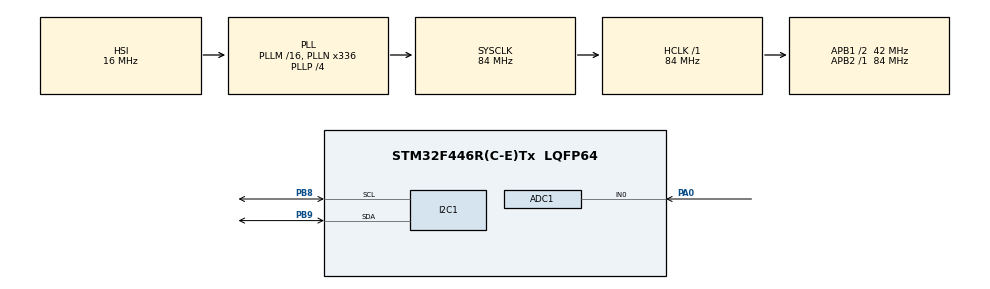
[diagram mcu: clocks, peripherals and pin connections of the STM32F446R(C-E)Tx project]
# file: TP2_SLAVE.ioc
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ADC1.Channel-0\#ChannelRegularConversion=ADC_CHANNEL_0
ADC1.Channel-1\#ChannelInjectedConversion=ADC_CHANNEL_0
ADC1.ContinuousConvMode=ENABLE
ADC1.EnableAnalogWatchDog=false
ADC1.InjNumberOfConversion=1
ADC1.InjectedOffset-1\#ChannelInjectedConversion=0
ADC1.InjectedRank-1\#ChannelInjectedConversion=1
ADC1.NbrOfConversion=1
ADC1.NbrOfConversionFlag=1
ADC1.Rank-0\#ChannelRegularConversion=1
ADC1.SamplingTime-0\#ChannelRegularConversion=ADC_SAMPLETIME_480CYCLES
ADC1.SamplingTime-1\#ChannelInjectedConversion=ADC_SAMPLETIME_3CYCLES
ADC1.master=1
I2C1.OwnAddress=0x13
Mcu.Family=STM32F4
Mcu.Name=STM32F446R(C-E)Tx
Mcu.Package=LQFP64
NVIC.I2C1_ER_IRQn=true\:0\:0\:false\:false\:true\:true\:true\:true
NVIC.I2C1_EV_IRQn=true\:0\:0\:false\:false\:true\:true\:true\:true
NVIC.PriorityGroup=NVIC_PRIORITYGROUP_0
PA0-WKUP.Signal=ADCx_IN0
PB8.Mode=I2C
PB8.Signal=I2C1_SCL
PB9.Mode=I2C
PB9.Signal=I2C1_SDA
ProjectManager.HeapSize=0x200
ProjectManager.StackSize=0x400
ProjectManager.TargetToolchain=STM32CubeIDE
RCC.48MHZClocksFreq_Value=84000000
RCC.AHBFreq_Value=84000000
RCC.APB1CLKDivider=RCC_HCLK_DIV2
RCC.APB1Freq_Value=42000000
RCC.APB1TimFreq_Value=84000000
RCC.APB2Freq_Value=84000000
RCC.APB2TimFreq_Value=84000000
RCC.CortexFreq_Value=84000000
RCC.FLatency-AdvancedSettings=FLASH_LATENCY_2
RCC.HCLKFreq_Value=84000000
RCC.HSE_VALUE=8000000
RCC.HSI_VALUE=16000000
RCC.PLLN=336
RCC.PLLP=RCC_PLLP_DIV4
RCC.SYSCLKFreq_VALUE=84000000
RCC.SYSCLKSource=RCC_SYSCLKSOURCE_PLLCLK
RCC.USBFreq_Value=168000000
RCC.VCOOutputFreq_Value=336000000
SH.ADCx_IN0.0=ADC1_IN0,IN0
board=NUCLEO-F446RE

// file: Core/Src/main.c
/* USER CODE BEGIN Header */
/**
  ******************************************************************************
  * @file           : main.c
  * @brief          : TP2 SLAVE - STM32F446RE I2C + ADC
  ******************************************************************************
  * Role of this board:
  * - I2C1 Slave on PB8/PB9.
  * - Own 7-bit address: 0x13.
  * - ADC1 input on PA0 / ADC1_IN0.
  * - Sends the ADC value to the Master as 2 bytes: MSB then LSB.
  ******************************************************************************
  */
/* USER CODE END Header */
#include "main.h"

/* USER CODE BEGIN Includes */
#include <stdio.h>
#include <string.h>
/* USER CODE END Includes */

ADC_HandleTypeDef hadc1;

I2C_HandleTypeDef hi2c1;

void SystemClock_Config(void);
static void MX_GPIO_Init(void);
static void MX_ADC1_Init(void);
static void MX_I2C1_Init(void);
/* USER CODE BEGIN PFP */
static uint16_t ADC_Read(void)
{
    HAL_ADC_Start(&hadc1);
    HAL_ADC_PollForConversion(&hadc1, HAL_MAX_DELAY);
    uint16_t val = (uint16_t)HAL_ADC_GetValue(&hadc1);
    HAL_ADC_Stop(&hadc1);
    return val;
}
/* USER CODE END PFP */

/* USER CODE BEGIN 0 */
volatile uint8_t cmd_received = 0;
volatile uint8_t tx_done = 0;
static uint8_t rx_buf[1] = {0};
static uint8_t tx_buf[2] = {0, 0};

void HAL_I2C_AddrCallback(I2C_HandleTypeDef *hi2c,
uint8_t TransferDirection,
uint16_t AddrMatchCode)
{
    if (TransferDirection == I2C_DIRECTION_TRANSMIT)
    {
        /* Master writing -> Slave receives */
        HAL_I2C_Slave_Seq_Receive_IT(hi2c, rx_buf, 1,
                I2C_FIRST_AND_LAST_FRAME);
    }
    else
    {
        /* Master reading -> Slave sends */
        HAL_I2C_Slave_Seq_Transmit_IT(hi2c, tx_buf, 2,
                I2C_FIRST_AND_LAST_FRAME);
    }
}

/* Called when slave has fully received 'Size' bytes from master */
void HAL_I2C_SlaveRxCpltCallback(I2C_HandleTypeDef *hi2c)
{
    HAL_I2C_EnableListen_IT(hi2c);
}

/* Called when slave has fully transmitted 'Size' bytes to master */
void HAL_I2C_SlaveTxCpltCallback(I2C_HandleTypeDef *hi2c)
{
    HAL_I2C_EnableListen_IT(hi2c);
}

void HAL_I2C_ListenCpltCallback(I2C_HandleTypeDef *hi2c)
{
    HAL_I2C_EnableListen_IT(hi2c);
}

void HAL_I2C_ErrorCallback(I2C_HandleTypeDef *hi2c)
{
    if (HAL_I2C_GetError(hi2c) == HAL_I2C_ERROR_AF ||
        HAL_I2C_GetError(hi2c) == HAL_I2C_ERROR_BERR)
    {
        HAL_I2C_EnableListen_IT(hi2c);
    }
}

/* USER CODE END 0 */

int main(void)
{

  /* MCU Configuration--------------------------------------------------------*/

  /* Reset of all peripherals, Initializes the Flash interface and the Systick. */
  HAL_Init();

  /* Configure the system clock */
  SystemClock_Config();

  /* Initialize all configured peripherals */
  MX_GPIO_Init();
  MX_ADC1_Init();
  MX_I2C1_Init();
  /* USER CODE BEGIN 2 */

      uint16_t adc_val;
      HAL_I2C_EnableListen_IT(&hi2c1);

  /* USER CODE END 2 */

  /* Infinite loop */
  /* USER CODE BEGIN WHILE */
  while (1)
      {
	  adc_val = ADC_Read();
	          tx_buf[0] = (uint8_t)(adc_val >> 8);
	          tx_buf[1] = (uint8_t)(adc_val & 0xFF);

	          HAL_Delay(500);

    /* USER CODE END WHILE */

      }
}

void SystemClock_Config(void)
{
  RCC_OscInitTypeDef RCC_OscInitStruct = {0};
  RCC_ClkInitTypeDef RCC_ClkInitStruct = {0};

  /** Configure the main internal regulator output voltage
  */
  __HAL_RCC_PWR_CLK_ENABLE();
  __HAL_PWR_VOLTAGESCALING_CONFIG(PWR_REGULATOR_VOLTAGE_SCALE3);

  /** Initializes the RCC Oscillators according to the specified parameters
  * in the RCC_OscInitTypeDef structure.
  */
  RCC_OscInitStruct.OscillatorType = RCC_OSCILLATORTYPE_HSI;
  RCC_OscInitStruct.HSIState = RCC_HSI_ON;
  RCC_OscInitStruct.HSICalibrationValue = RCC_HSICALIBRATION_DEFAULT;
  RCC_OscInitStruct.PLL.PLLState = RCC_PLL_ON;
  RCC_OscInitStruct.PLL.PLLSource = RCC_PLLSOURCE_HSI;
  RCC_OscInitStruct.PLL.PLLM = 16;
  RCC_OscInitStruct.PLL.PLLN = 336;
  RCC_OscInitStruct.PLL.PLLP = RCC_PLLP_DIV4;
  RCC_OscInitStruct.PLL.PLLQ = 2;
  RCC_OscInitStruct.PLL.PLLR = 2;
  if (HAL_RCC_OscConfig(&RCC_OscInitStruct) != HAL_OK)
  {
    Error_Handler();
  }

  /** Initializes the CPU, AHB and APB buses clocks
  */
  RCC_ClkInitStruct.ClockType = RCC_CLOCKTYPE_HCLK|RCC_CLOCKTYPE_SYSCLK
                              |RCC_CLOCKTYPE_PCLK1|RCC_CLOCKTYPE_PCLK2;
  RCC_ClkInitStruct.SYSCLKSource = RCC_SYSCLKSOURCE_PLLCLK;
  RCC_ClkInitStruct.AHBCLKDivider = RCC_SYSCLK_DIV1;
  RCC_ClkInitStruct.APB1CLKDivider = RCC_HCLK_DIV2;
  RCC_ClkInitStruct.APB2CLKDivider = RCC_HCLK_DIV1;

  if (HAL_RCC_ClockConfig(&RCC_ClkInitStruct, FLASH_LATENCY_2) != HAL_OK)
  {
    Error_Handler();
  }
}

static void MX_ADC1_Init(void)
{

  ADC_ChannelConfTypeDef sConfig = {0};
  ADC_InjectionConfTypeDef sConfigInjected = {0};

  /** Configure the global features of the ADC (Clock, Resolution, Data Alignment and number of conversion)
  */
  hadc1.Instance = ADC1;
  hadc1.Init.ClockPrescaler = ADC_CLOCK_SYNC_PCLK_DIV4;
  hadc1.Init.Resolution = ADC_RESOLUTION_12B;
  hadc1.Init.ScanConvMode = DISABLE;
  hadc1.Init.ContinuousConvMode = ENABLE;
  hadc1.Init.DiscontinuousConvMode = DISABLE;
  hadc1.Init.ExternalTrigConvEdge = ADC_EXTERNALTRIGCONVEDGE_NONE;
  hadc1.Init.ExternalTrigConv = ADC_SOFTWARE_START;
  hadc1.Init.DataAlign = ADC_DATAALIGN_RIGHT;
  hadc1.Init.NbrOfConversion = 1;
  hadc1.Init.DMAContinuousRequests = DISABLE;
  hadc1.Init.EOCSelection = ADC_EOC_SINGLE_CONV;
  if (HAL_ADC_Init(&hadc1) != HAL_OK)
  {
    Error_Handler();
  }

  /** Configure for the selected ADC regular channel its corresponding rank in the sequencer and its sample time.
  */
  sConfig.Channel = ADC_CHANNEL_0;
  sConfig.Rank = 1;
  sConfig.SamplingTime = ADC_SAMPLETIME_480CYCLES;
  if (HAL_ADC_ConfigChannel(&hadc1, &sConfig) != HAL_OK)
  {
    Error_Handler();
  }

  /** Configures for the selected ADC injected channel its corresponding rank in the sequencer and its sample time
  */
  sConfigInjected.InjectedChannel = ADC_CHANNEL_0;
  sConfigInjected.InjectedRank = 1;
  sConfigInjected.InjectedNbrOfConversion = 1;
  sConfigInjected.InjectedSamplingTime = ADC_SAMPLETIME_3CYCLES;
  sConfigInjected.ExternalTrigInjecConvEdge = ADC_EXTERNALTRIGINJECCONVEDGE_NONE;
  sConfigInjected.ExternalTrigInjecConv = ADC_INJECTED_SOFTWARE_START;
  sConfigInjected.AutoInjectedConv = DISABLE;
  sConfigInjected.InjectedDiscontinuousConvMode = DISABLE;
  sConfigInjected.InjectedOffset = 0;
  if (HAL_ADCEx_InjectedConfigChannel(&hadc1, &sConfigInjected) != HAL_OK)
  {
    Error_Handler();
  }

}

static void MX_I2C1_Init(void)
{

  hi2c1.Instance = I2C1;
  hi2c1.Init.ClockSpeed = 100000;
  hi2c1.Init.DutyCycle = I2C_DUTYCYCLE_2;
  hi2c1.Init.OwnAddress1 = 38;
  hi2c1.Init.AddressingMode = I2C_ADDRESSINGMODE_7BIT;
  hi2c1.Init.DualAddressMode = I2C_DUALADDRESS_DISABLE;
  hi2c1.Init.OwnAddress2 = 0;
  hi2c1.Init.GeneralCallMode = I2C_GENERALCALL_DISABLE;
  hi2c1.Init.NoStretchMode = I2C_NOSTRETCH_DISABLE;
  if (HAL_I2C_Init(&hi2c1) != HAL_OK)
  {
    Error_Handler();
  }

}

static void MX_GPIO_Init(void)
{

  /* GPIO Ports Clock Enable */
  __HAL_RCC_GPIOA_CLK_ENABLE();
  __HAL_RCC_GPIOB_CLK_ENABLE();

}

void Error_Handler(void)
{
  __disable_irq();
  while (1)
  {
  }
}
